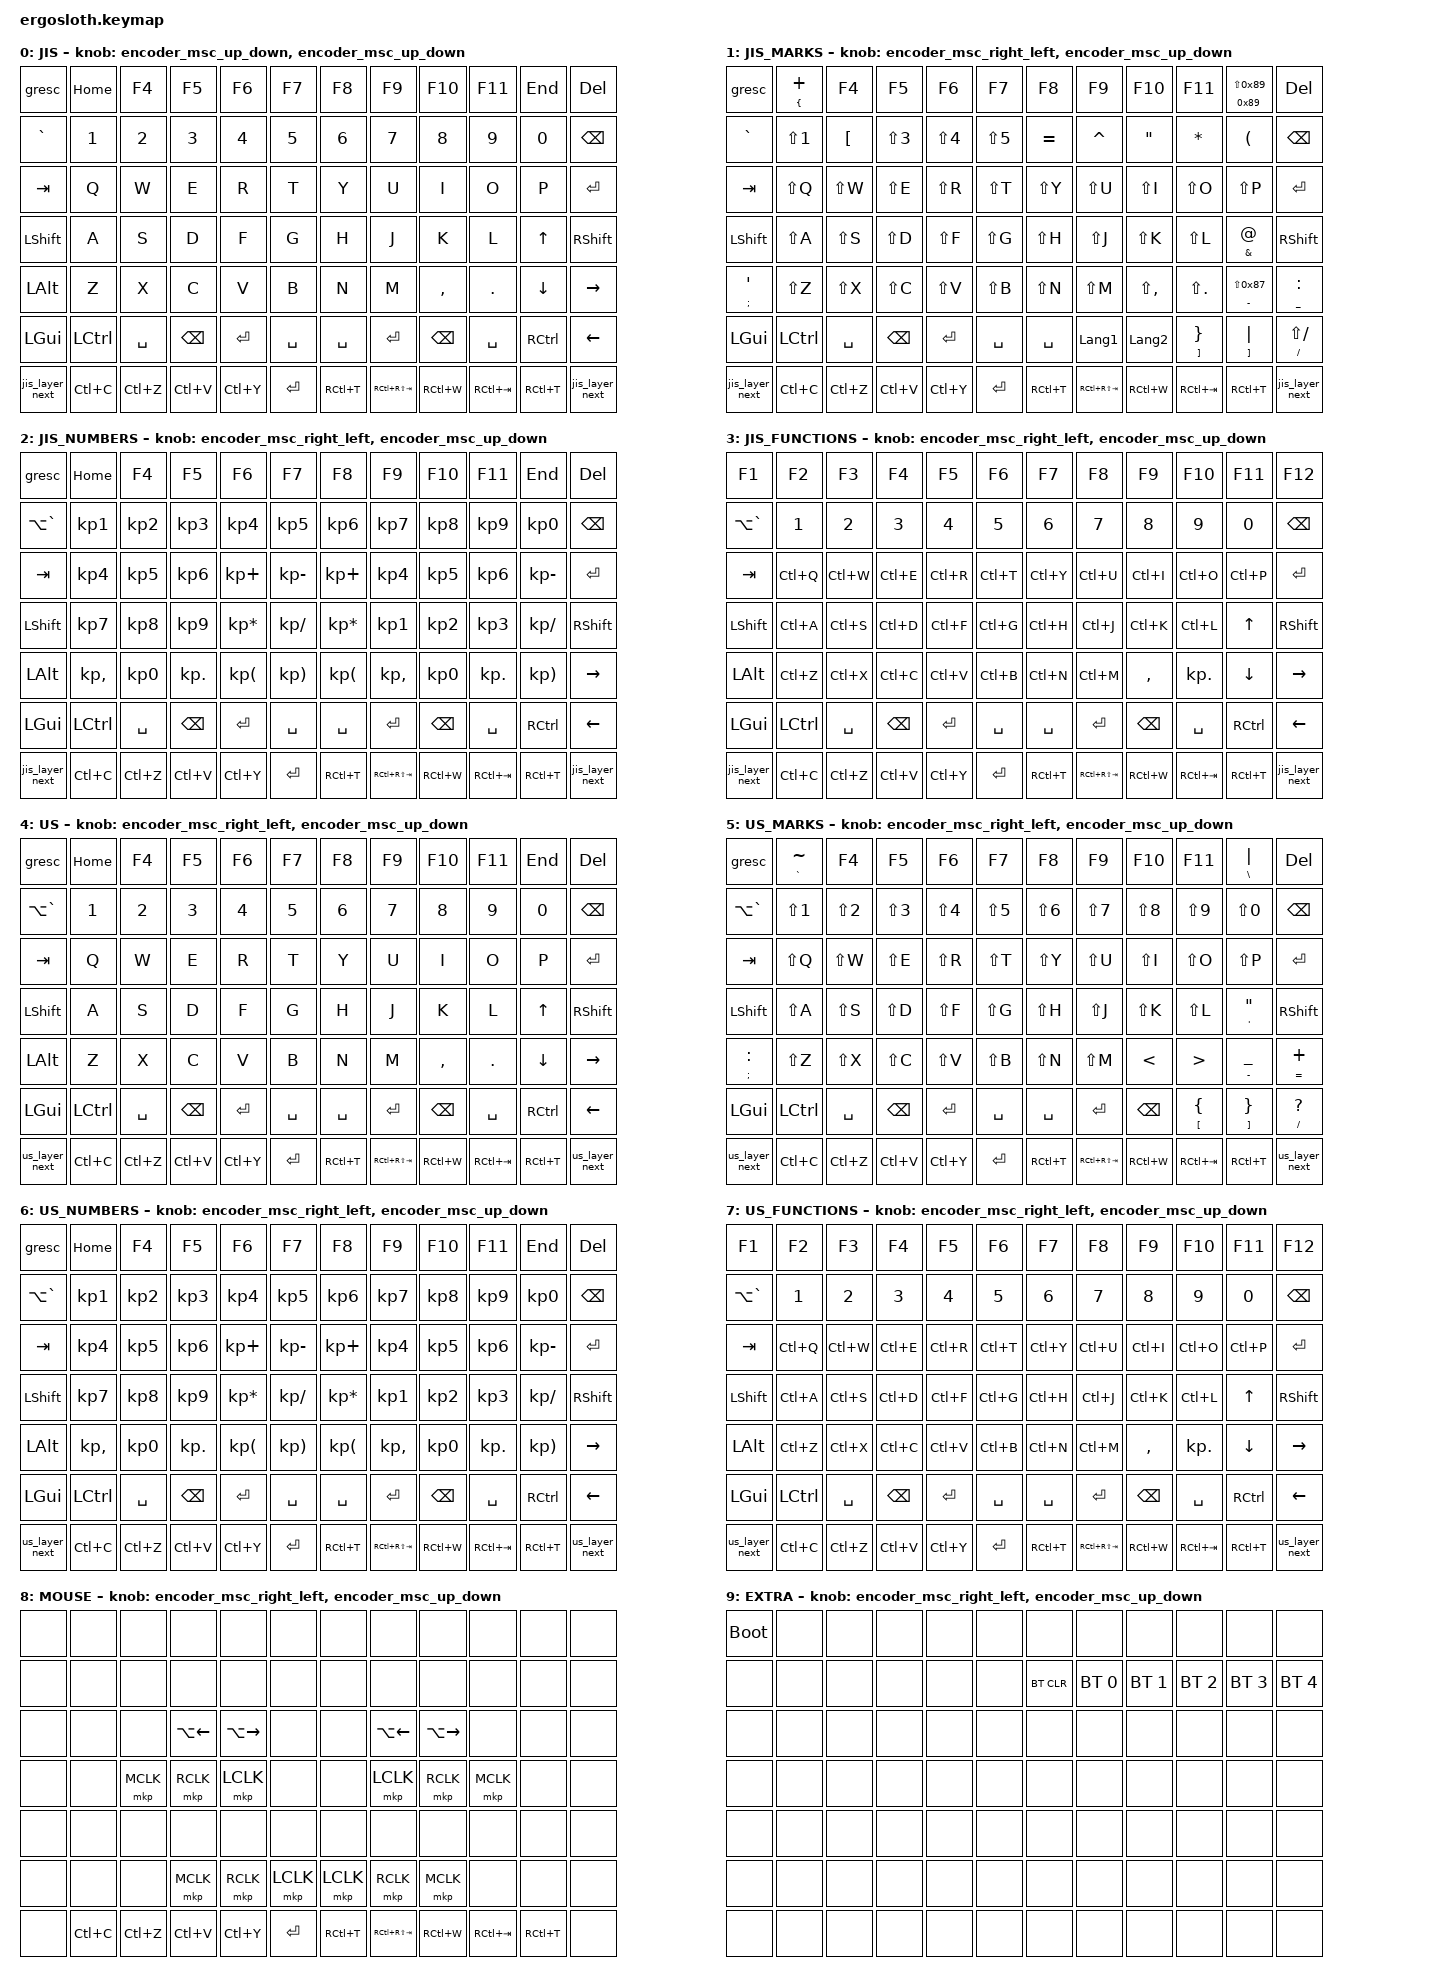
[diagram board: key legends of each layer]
/*
 * Copyright (c) 2020 The ZMK Contributors
 *
 * SPDX-License-Identifier: MIT
 */

#include <input/processors.dtsi>

#define ZMK_POINTING_DEFAULT_SCRL_VAL 50
#define ZMK_MOUSE_SCRL_VAL 50

#include <zephyr/dt-bindings/input/input-event-codes.h>
#include <behaviors.dtsi>
#include <dt-bindings/zmk/bt.h>
#include <dt-bindings/zmk/keys.h>
#include <dt-bindings/zmk/pointing.h>

#define JIS_L       0
#define JIS_MARKS_L 1
#define JIS_NUMS_L  2
#define JIS_FUNCS_L 3
#define US_L        4
#define US_MARKS_L  5
#define US_NUMS_L   6
#define US_FUNCS_L  7
#define MOUSE_L     8
#define EXTRA_L     9

// OS設定を日本語キーボードのまま使用するための変換定義

#define JP_DQUOTE       AT                // "
#define JP_AMPERSAND    CARET             // &
#define JP_QUOTE        AMPERSAND         // '
#define JP_EQUAL        UNDER             // =
#define JP_CARET        EQUAL             // ^
#define JP_YEN          0x89              // ¥
#define JP_PLUS         COLON             // +
#define JP_TILDE        PLUS              // ~
#define JP_PIPE         LS(0x89)          // |
#define JP_AT           LEFT_BRACKET      // @
#define JP_COLON        SINGLE_QUOTE      // :
#define JP_ASTERISK     DOUBLE_QUOTES     // *
#define JP_BACKQUOTE    LEFT_BRACE        // `
#define JP_UNDERSCORE   LS(0x87)          // _
#define JP_LBRACKET     RIGHT_BRACKET     // [
#define JP_RBRACKET     BACKSLASH         // ]
#define JP_LPAREN       ASTERISK          // (
#define JP_RPAREN       LEFT_PARENTHESIS  // )
#define JP_LBRACE       RIGHT_BRACE       // {
#define JP_RBRACE       PIPE              // }
#define JP_KANA         LANGUAGE_1        // かな
#define JP_EISU         LANGUAGE_2        // 英数
#define JP_HANZEN       GRAVE             // 半角/全角

/**************************************************************************/
/*  TrackBall 関連                                                        */

&trackball_right { cpi = <600>; };

&trackball_right_listener { input-processors = <&zip_temp_layer MOUSE_L 5000>; };

// クリック時に10秒間AMLを延長

&mkp_input_listener { input-processors = <&zip_temp_layer MOUSE_L 10000>; };

// キー入力から200ms間はAMLを抑制(AML誤発動防止)

&zip_temp_layer { require-prior-idle-ms = <200>; };

/**************************************************************************/
/*   マウススクロール用設定                                               */

/ {
    input_processors {
        zip_wheel_scaler: zip_wheel_scaler {
            compatible = "zmk,input-processor-scaler";
            #input-processor-cells = <2>;
            type = <INPUT_EV_REL>;
            codes = <INPUT_REL_WHEEL>;
            track-remainders;
        };
    };
};

&msc {
    delay-ms = <0>;
    trigger-period-ms = <10>;
    time-to-max-speed-ms = <0>;
    acceleration-exponent = <0>;
};

&msc_input_listener {
    warp {
        layers = <MOUSE_L>;
        input-processors = <&zip_wheel_scaler 4 1>;
    };

    normal {
        layers = <JIS_L JIS_MARKS_L JIS_NUMS_L JIS_FUNCS_L US_L US_MARKS_L US_NUMS_L US_FUNCS_L EXTRA_L>;
        input-processors = <&zip_wheel_scaler 1 1>;
    };
};

/**************************************************************************/

/ {
    combos {
        compatible = "zmk,combos";

        combo_esc {
            layers = <JIS_L>;
            timeout-ms = <50>;
            key-positions = <0 1>;
            bindings = <&kp ESC>;
        };
    };

    /**************************************************************************/

    macros {
        ctrl_tab: ctrl_tab {
            compatible = "zmk,behavior-macro";
            #binding-cells = <0>;
            wait-ms = <40>;
            tap-ms = <40>;
            bindings =
                <&macro_press>,
                <&kp LCTRL &kp TAB>,
                <&macro_tap_time 1000>,
                <&macro_release>,
                <&kp LCTRL>;
        };

        ctrl_shift_tab: ctrl_shift_tab {
            compatible = "zmk,behavior-macro";
            #binding-cells = <0>;
            wait-ms = <40>;
            tap-ms = <40>;
            bindings =
                <&macro_press>,
                <&kp LCTRL>,
                <&macro_press>,
                <&kp LSHIFT &kp TAB>,
                <&macro_release>,
                <&kp LSHIFT>,
                <&macro_tap_time 1000>,
                <&macro_release>,
                <&kp LCTRL>;
        };

        alt_tab: alt_tab {
            compatible = "zmk,behavior-macro";
            #binding-cells = <0>;
            wait-ms = <40>;
            tap-ms = <40>;
            bindings =
                <&macro_press>,
                <&kp LALT &kp TAB>,
                <&macro_tap_time 1000>,
                <&macro_release>,
                <&kp LALT>;
        };

        alt_shift_tab: alt_shift_tab {
            compatible = "zmk,behavior-macro";
            #binding-cells = <0>;
            wait-ms = <40>;
            tap-ms = <40>;
            bindings =
                <&macro_press>,
                <&kp LALT>,
                <&macro_press>,
                <&kp LSHIFT &kp TAB>,
                <&macro_release>,
                <&kp LSHIFT>,
                <&macro_tap_time 1000>,
                <&macro_release>,
                <&kp LALT>;
        };

        sleep_windows: sleep_windows {
            compatible = "zmk,behavior-macro";
            #binding-cells = <0>;
            wait-ms = <40>;
            tap-ms = <40>;
            bindings =
                <&macro_press>,
                <&kp LGUI &kp X>,
                <&macro_release>,
                <&kp LGUI &kp U>,
                <&macro_tap_time 100>,
                <&kp S>;
        };


        jis_layer_next: jis_layer_next {
            compatible = "zmk,behavior-macro";
            label = "JIS_LAYER_NEXT";
            #binding-cells = <0>;
            // bindings = <&if &layer-0 &to 1 &if &layer-1 &to 2 &if &layer-2 &to 3 &if &layer-3 &to 0>;
            bindings = <&macro_tap_time 1000>, <&macro_tap  &to 0>;
        };

        jis_layer_prev: jis_layer_prev {
            compatible = "zmk,behavior-macro";
            label = "JIS_LAYER_PREV";
            #binding-cells = <0>;
            // bindings = <&if &layer-0 &to 3 &if &layer-1 &to 0 &if &layer-2 &to 1 &if &layer-3 &to 2>;
            bindings = <&macro_tap_time 1000>, <&macro_tap  &to 0>;
        };

        us_layer_next: us_layer_next {
            compatible = "zmk,behavior-macro";
            label = "US_LAYER_NEXT";
            #binding-cells = <0>;
            // bindings = <&if &layer-4 &to 5 &if &layer-5 &to 6 &if &layer-6 &to 7 &if &layer-7 &to 4>;
            bindings = <&macro_tap_time 1000>, <&macro_tap  &to 0>;
        };

        us_layer_prev: us_layer_prev {
            compatible = "zmk,behavior-macro";
            label = "US_LAYER_PREV";
            #binding-cells = <0>;
            // bindings = <&if &layer-4 &to 7 &if &layer-5 &to 4 &if &layer-6 &to 5 &if &layer-7 &to 6>;
            bindings = <&macro_tap_time 1000>, <&macro_tap  &to 0>;
        };

    };

    /**************************************************************************/

    behaviors {
        td_bspc: tap_dance_0 {
            compatible = "zmk,behavior-tap-dance";
            #binding-cells = <0>;
            tapping-term-ms = <200>;
            bindings = <&lt JIS_FUNCS_L BSPC>, <&kp BSPC>;
        };

        td_spc: tap_dance_1 {
            compatible = "zmk,behavior-tap-dance";
            #binding-cells = <0>;
            tapping-term-ms = <200>;
            bindings = <&lt JIS_FUNCS_L SPACE>, <&kp SPACE>;
        };

        mouse_scroll: mouse_wheel_scroll {
            compatible = "zmk,behavior-sensor-rotate-var";
            #sensor-binding-cells = <2>;
            bindings = <&msc>, <&msc>;

            tap-ms = <25>;
        };

        mod_mkp: mod_mkp {
            compatible = "zmk,behavior-hold-tap";
            label = "MOD_MKP";
            bindings = <&kp>, <&mkp>;

            #binding-cells = <2>;
            tapping-term-ms = <150>;
        };

        tog_off: toggle_layer_off {
            compatible = "zmk,behavior-toggle-layer";
            #binding-cells = <1>;
            display-name = "Toggle Layer Off";
            toggle-mode = "off";
        };

        ime_alt: ime_alt {
            compatible = "zmk,behavior-hold-tap";
            label = "IME_ALT";
            bindings = <&kp>, <&kp>;

            #binding-cells = <2>;
            tapping-term-ms = <200>;
            flavor = "tap-preferred";
        };

        encoder_msc_up_down: encoder_msc_up_down {
            compatible = "zmk,behavior-sensor-rotate";
            label = "ENCODER_MSC_UP_DOWN";
            #sensor-binding-cells = <0>;
            bindings = <&msc SCRL_UP>, <&msc SCRL_DOWN>;

            tap-ms = <20>;
        };

        encoder_msc_right_left: encoder_msc_right_left {
            compatible = "zmk,behavior-sensor-rotate";
            label = "ENCODER_MSC_RIGHT_LEFT";
            #sensor-binding-cells = <0>;
            bindings = <&msc SCRL_RIGHT>, <&msc SCRL_LEFT>;

            tap-ms = <20>;
        };

        encoder_vol_up_down: encoder_vol_up_down {
            compatible = "zmk,behavior-sensor-rotate";
            #sensor-binding-cells = <0>;
            bindings = <&kp C_VOLUME_UP>, <&kp C_VOLUME_DOWN>;

            tap-ms = <20>;
        };

        encoder_bri_up_down: encoder_bri_up_down {
            compatible = "zmk,behavior-sensor-rotate";
            #sensor-binding-cells = <0>;
            bindings = <&kp C_BRIGHTNESS_INC>, <&kp C_BRIGHTNESS_DEC>;

            tap-ms = <20>;
        };

        encoder_ctrl_tab: encoder_ctrl_tab {
            compatible = "zmk,behavior-sensor-rotate";
            #sensor-binding-cells = <0>;
            bindings = <&ctrl_tab>, <&ctrl_shift_tab>;

            tap-ms = <20>;
        };

        encoder_alt_tab: encoder_alt_tab {
            compatible = "zmk,behavior-sensor-rotate";
            #sensor-binding-cells = <0>;
            bindings = <&alt_tab>, <&alt_shift_tab>;

            tap-ms = <20>;
        };

        encoder_next_prev: encoder_next_prev {
            compatible = "zmk,behavior-sensor-rotate";
            #sensor-binding-cells = <0>;
            bindings = <&kp LA(RIGHT)>, <&kp LA(LEFT)>;

            tap-ms = <20>;
        };

        encoder_tab: encoder_tab {
            compatible = "zmk,behavior-sensor-rotate";
            #sensor-binding-cells = <0>;
            bindings = <&kp TAB>, <&kp LS(TAB)>;

            tap-ms = <20>;
        };


        encoder_jis_layer: encoder_jis_layer {
            compatible = "zmk,behavior-sensor-rotate";
            #sensor-binding-cells = <0>;
            bindings = <&jis_layer_next>, <&jis_layer_prev>;
            tap-ms = <20>;
        };

        encoder_us_layer: encoder_us_layer {
            compatible = "zmk,behavior-sensor-rotate";
            #sensor-binding-cells = <0>;
            bindings = <&us_layer_next>, <&us_layer_prev>;
            tap-ms = <20>;
        };

    };

    /**************************************************************************/

    keymap {
        compatible = "zmk,keymap";

        //               | SW2  | SW3  | SW4  | SW5  |   | SW6  | SW7  | SW8  | SW9  |
        // | SW0  | SW1  | SW14 | SW15 | SW16 | SW17 |   | SW18 | SW19 | SW20 | SW21 | SW10 | SW11 |
        // | SW12 | SW13 | SW26 | SW27 | SW28 | SW29 |   | SW30 | SW31 | SW32 | SW33 | SW22 | SW23 |
        // | SW24 | SW25 | SW38 | SW39 | SW40 | SW41 |   | SW42 | SW43 | SW44 | SW45 | SW34 | SW35 |
        // | SW36 | SW37 | SW50 | SW51 | SW52 | SW53 |   | SW54 | SW55 | SW56 | SW57 | SW46 | SW47 |
        // | SW48 | SW49 | SW60 | SW61 | SW62 | (LAJS)   (RAJS) | SW69 | SW70 | SW71 | SW58 | SW59 |
        //                                  (TouchPad)
        // 		                              | SW65 |   | SW66 |	    (TrackBall)
        // 							   | SW64 |					| SW67 |
        // | SW72 |				| SW63 |							   | SW68 |				| SW83 |
        //    (LeftRotaryEncoder)                                             (RightRotaryEncoder)
        //		  | SW73 |															 | SW78 |
        // | SW74 | SW77 | SW76 |											  | SW79 | SW82 | SW81 |
        // 		  | SW75 |															 | SW80 |
        //                                                         ||
        //                                                       __||__
        //                                                        \  /
        //                                                         \/
        // | SW0  | SW1  | SW2  | SW3  | SW4  | SW5  |   | SW6  | SW7  | SW8  | SW9  | SW10 | SW11 |
        // | SW12 | SW13 | SW14 | SW15 | SW16 | SW17 |   | SW18 | SW19 | SW20 | SW21 | SW22 | SW23 |
        // | SW24 | SW25 | SW26 | SW27 | SW28 | SW29 |   | SW30 | SW31 | SW32 | SW33 | SW34 | SW35 |
        // | SW36 | SW37 | SW38 | SW39 | SW40 | SW41 |   | SW42 | SW43 | SW44 | SW45 | SW46 | SW47 |
        // | SW48 | SW49 | SW50 | SW51 | SW52 | SW53 |   | SW54 | SW55 | SW56 | SW57 | SW58 | SW59 |
        // | SW60 | SW61 | SW62 | SW63 | SW64 | SW65 |   | SW66 | SW67 | SW68 | SW69 | SW70 | SW71 |
        // | SW72 | SW73 | SW74 | SW75 | SW76 | SW77 |   | SW78 | SW79 | SW80 | SW81 | SW82 | SW83 |

        jis_layer {
            display-name = "JIS";

            // -----------------------------------------------------------------------------------------
            //               |  F4  |  F5  |  F6  |  F7  |   |  F8  |  F9  | F10  | F11  |
            // |  ESC | HOME |   2  |   3  |   4  |   5  |   |   6  |   7  |   8  |   9  |  END |  DEL |
            // |  E/J |   1  |   W  |   E  |   R  |   T  |   |   Y  |   U  |   I  |   O  |   0  | BKSP |
            // |  TAB |   Q  |   S  |   D  |   F  |   G  |   |   H  |   J  |   K  |   L  |   P  | ENTR |
            // | LSft |   A  |   X  |   C  |   V  |   B  |   |   N  |   M  |   ,  |   .  |   ↑  | RSft |
            // | LAlt |   Z  |  GUI | LCtr | SPCE |                 | SPCE | RCtr |   ←  |   ↓  |   →  |
            // 		                      	
            //                                    | SPCE |   | SPCE |
            // 							   | ENTR |					| ENTR |
            // | layr |				| BKSP |							   | BKSP |				| layr |
            //
            //		  | CtrC |															 | CtrT |
            // | CtrZ | Entr | CtrY |											  | CSTb | Entr | CtTb |
            // 		  | CtrV |															 | CtrW |
            // -----------------------------------------------------------------------------------------
            // |  ESC | HOME |  F4  |  F5  |  F6  |  F7  |   |  F8  |  F9  | F10  | F11  |  END |  DEL |
            // |  E/J |   1  |   2  |   3  |   4  |   5  |   |   6  |   7  |   8  |   9  |   0  | BKSP |
            // |  TAB |   Q  |   W  |   E  |   R  |   T  |   |   Y  |   U  |   I  |   O  |   P  | ENTR |
            // | LSft |   A  |   S  |   D  |   F  |   G  |   |   H  |   J  |   K  |   L  |   ↑  | RSft |
            // | LAlt |   Z  |   X  |   C  |   V  |   B  |   |   N  |   M  |   ,  |   .  |   ↓  |   →  |
            // |  GUI | LCtr | SPCE | BKSP | ENTR | SPCE |   | SPCE | ENTR | BKSP | SPCE | RCtr |   ←  |
            // | lyr1 | CtrC | CtrZ | CtrV | CtrY | Entr |   | CtrT | BTab | CtrW | NTab | CtrT | lyr1 |

            bindings = <
&gresc     &kp HOME   &kp F4     &kp F5         &kp F6     &kp F7     &kp F8     &kp F9           &kp F10        &kp F11      &kp END    &kp DEL
&kp GRAVE  &kp N1     &kp N2     &kp N3         &kp N4     &kp N5     &kp N6     &kp N7           &kp N8         &kp N9       &kp N0     &kp BACKSPACE
&kp TAB    &kp Q      &kp W      &kp E          &kp R      &kp T      &kp Y      &kp U            &kp I          &kp O        &kp P      &kp ENTER
&kp LSHFT  &kp A      &kp S      &kp D          &kp F      &kp G      &kp H      &kp J            &kp K          &kp L        &kp UP     &kp RSHFT
&kp LALT   &kp Z      &kp X      &kp C          &kp V      &kp B      &kp N      &kp M            &kp COMMA      &kp PERIOD   &kp DOWN   &kp RIGHT
&kp LGUI   &kp LCTRL  &kp SPACE  &kp BACKSPACE  &kp ENTER  &kp SPACE  &kp SPACE  &kp ENTER        &kp BACKSPACE  &kp SPACE    &kp RCTRL  &kp LEFT
&jis_layer_next  &kp LC(C)  &kp LC(Z)  &kp LC(V)      &kp LC(Y)  &kp ENTER  &kp RC(T)  &kp RC(RS(TAB))  &kp RC(W)      &kp RC(TAB)  &kp RC(T)  &jis_layer_next
            >;

            sensor-bindings = <&encoder_msc_up_down>, <&encoder_msc_up_down>;
        };

        jis_mark_layer {
            display-name = "JIS_MARKS";

            // -----------------------------------------------------------------------------------------
            // |  ESC |  ` ~ |  F4  |  F5  |  F6  |  F7  |   |  F8  |  F9  | F10  | F11  |  \ | |  DEL |
            // |  E/J |   !  |   @  |   #  |   $  |   %  |   |   ^  |   &  |   *  |   (  |   )  | BKSP |
            // |  TAB |   Q  |   W  |   E  |   R  |   T  |   |   Y  |   U  |   I  |   O  |   P  | ENTR |
            // | LSft |   A  |   S  |   D  |   F  |   G  |   |   H  |   J  |   K  |   L  |  ' " | RSft |
            // |  ; : |   Z  |   X  |   C  |   V  |   B  |   |   N  |   M  |   <  |   >  |  - _ |  = + |
            // |  GUI | LCtr | SPCE | BKSP | ENTR | SPCE |   | SPCE | Kana | EiSu |  [ { |  ] } |  / ? |
            // | lyr2 | CtrC | CtrZ | CtrV | CtrY | Entr |   | CtrT | BTab | CtrW | NTab | CtrT | lyr2 |

            bindings = <
&gresc                      &mt LEFT_BRACE PLUS  &kp F4            &kp F5         &kp F6      &kp F7      &kp F8     &kp F9           &kp F10            &kp F11                        &mt 0x89 LS(0x89)       &kp DEL
&kp GRAVE                   &kp LS(N1)           &kp LEFT_BRACKET  &kp LS(N3)     &kp LS(N4)  &kp LS(N5)  &kp EQUAL  &kp CARET        &kp DOUBLE_QUOTES  &kp ASTERISK                   &kp LEFT_PARENTHESIS    &kp BACKSPACE
&kp TAB                     &kp LS(Q)            &kp LS(W)         &kp LS(E)      &kp LS(R)   &kp LS(T)   &kp LS(Y)  &kp LS(U)        &kp LS(I)          &kp LS(O)                      &kp LS(P)               &kp ENTER
&kp LSHFT                   &kp LS(A)            &kp LS(S)         &kp LS(D)      &kp LS(F)   &kp LS(G)   &kp LS(H)  &kp LS(J)        &kp LS(K)          &kp LS(L)                      &mt AMPERSAND AT        &kp RSHFT
&mt SEMICOLON SINGLE_QUOTE  &kp LS(Z)            &kp LS(X)         &kp LS(C)      &kp LS(V)   &kp LS(B)   &kp LS(N)  &kp LS(M)        &kp LS(COMMA)      &kp LS(PERIOD)                 &mt MINUS LS(0x87)      &mt UNDER COLON
&kp LGUI                    &kp LCTRL            &kp SPACE         &kp BACKSPACE  &kp ENTER   &kp SPACE   &kp SPACE  &kp LANGUAGE_1   &kp LANGUAGE_2     &mt RIGHT_BRACKET RIGHT_BRACE  &mt RIGHT_BRACKET PIPE  &mt SLASH LS(SLASH)
&jis_layer_next             &kp LC(C)            &kp LC(Z)         &kp LC(V)      &kp LC(Y)   &kp ENTER   &kp RC(T)  &kp RC(RS(TAB))  &kp RC(W)          &kp RC(TAB)                    &kp RC(T)               &jis_layer_next
            >;

            sensor-bindings = <&encoder_msc_right_left &encoder_msc_up_down>;
        };

        jis_num_layer {
            display-name = "JIS_NUMBERS";

            // -----------------------------------------------------------------------------------------
            // |  ESC | HOME |  F4  |  F5  |  F6  |  F7  |   |  F8  |  F9  | F10  | F11  |  END |  DEL |
            // |  E/J |   1  |   2  |   3  |   4  |   5  |   |   6  |   7  |   8  |   9  |   0  | BKSP |
            // |  TAB |   4  |   5  |   6  |   +  |   -  |   |   +  |   4  |   5  |   6  |   -  | ENTR |
            // | LSft |   7  |   8  |   9  |   *  |   /  |   |   *  |   1  |   2  |   3  |   /  | RSft |
            // | LAlt |   ,  |   0  |   .  |   (  |   )  |   |   (  |   ,  |   0  |   .  |   )  |   →  |
            // |  GUI | LCtr | SPCE | BKSP | ENTR | SPCE |   | SPCE | ENTR | BKSP | SPCE | RCtr |   ←  |
            // | lyr5 | CtrC | CtrZ | CtrV | CtrY | Entr |   | CtrT | BTab | CtrW | NTab | CtrT | lyr5 |

            bindings = <
&gresc         &kp HOME      &kp F4     &kp F5         &kp F6           &kp F7         &kp F8           &kp F9           &kp F10        &kp F11      &kp END        &kp DEL
&kp LA(GRAVE)  &kp KP_N1     &kp KP_N2  &kp KP_N3      &kp KP_N4        &kp KP_N5      &kp KP_N6        &kp KP_N7        &kp KP_N8      &kp KP_N9    &kp KP_N0      &kp BACKSPACE
&kp TAB        &kp KP_N4     &kp KP_N5  &kp KP_N6      &kp KP_PLUS      &kp KP_MINUS   &kp KP_PLUS      &kp KP_N4        &kp KP_N5      &kp KP_N6    &kp KP_MINUS   &kp ENTER
&kp LSHFT      &kp KP_N7     &kp KP_N8  &kp KP_N9      &kp KP_MULTIPLY  &kp KP_DIVIDE  &kp KP_MULTIPLY  &kp KP_N1        &kp KP_N2      &kp KP_N3    &kp KP_DIVIDE  &kp RSHFT
&kp LALT       &kp KP_COMMA  &kp KP_N0  &kp KP_DOT     &kp KP_LPAR      &kp KP_RPAR    &kp KP_LPAR      &kp KP_COMMA     &kp KP_N0      &kp KP_DOT   &kp KP_RPAR    &kp RIGHT
&kp LGUI       &kp LCTRL     &kp SPACE  &kp BACKSPACE  &kp ENTER        &kp SPACE      &kp SPACE        &kp ENTER        &kp BACKSPACE  &kp SPACE    &kp RCTRL      &kp LEFT
&jis_layer_next   &kp LC(C)     &kp LC(Z)  &kp LC(V)      &kp LC(Y)        &kp ENTER      &kp RC(T)        &kp RC(RS(TAB))  &kp RC(W)      &kp RC(TAB)  &kp RC(T)      &jis_layer_next
            >;

            sensor-bindings = <&encoder_msc_right_left &encoder_msc_up_down>;
        };

        jis_func_layer {
            display-name = "JIS_FUNCTIONS";

            // -----------------------------------------------------------------------------------------
            // |  F1  |  F2  |  F3  |  F4  |  F5  |  F6  |   |  F7  |  F8  |  F9  | F10  |  F11 |  F12 |
            // |  E/J |   1  |   2  |   3  |   4  |   5  |   |   6  |   7  |   8  |   9  |   0  | BKSP |
            // |  TAB | CtrQ | CtrW | CtrE | CtrR | CtrT |   | CtrY | CtrU | CtrI | CtrO | CtrP | ENTR |
            // | LSft | CtrA | CtrS | CtrD | CtrF | CtrG |   | CtrH | CtrJ | CtrK | CtrL |   ↑  | RSft |
            // | LAlt | CtrZ | CtrX | CtrC | CtrV | CtrB |   | CtrN | CtrM |   ,  |   .  |   ↓  |   →  |
            // |  GUI | LCtr | SPCE | BKSP | ENTR | SPCE |   | SPCE | ENTR | BKSP | SPCE | RCtr |   ←  |
            // | lyr0 | CtrC | CtrZ | CtrV | CtrY | Entr |   | CtrT | BTab | CtrW | NTab | CtrT | lyr0 |

            bindings = <
&kp F1         &kp F2     &kp F3     &kp F4         &kp F5     &kp F6     &kp F7     &kp F8           &kp F9         &kp F10      &kp F11    &kp F12
&kp LA(GRAVE)  &kp N1     &kp N2     &kp N3         &kp N4     &kp N5     &kp N6     &kp N7           &kp N8         &kp N9       &kp N0     &kp BACKSPACE
&kp TAB        &kp LC(Q)  &kp LC(W)  &kp LC(E)      &kp LC(R)  &kp LC(T)  &kp LC(Y)  &kp LC(U)        &kp LC(I)      &kp LC(O)    &kp LC(P)  &kp ENTER
&kp LSHFT      &kp LC(A)  &kp LC(S)  &kp LC(D)      &kp LC(F)  &kp LC(G)  &kp LC(H)  &kp LC(J)        &kp LC(K)      &kp LC(L)    &kp UP     &kp RSHFT
&kp LALT       &kp LC(Z)  &kp LC(X)  &kp LC(C)      &kp LC(V)  &kp LC(B)  &kp LC(N)  &kp LC(M)        &kp COMMA      &kp KP_DOT   &kp DOWN   &kp RIGHT
&kp LGUI       &kp LCTRL  &kp SPACE  &kp BACKSPACE  &kp ENTER  &kp SPACE  &kp SPACE  &kp ENTER        &kp BACKSPACE  &kp SPACE    &kp RCTRL  &kp LEFT
&jis_layer_next  &kp LC(C)  &kp LC(Z)  &kp LC(V)      &kp LC(Y)  &kp ENTER  &kp RC(T)  &kp RC(RS(TAB))  &kp RC(W)      &kp RC(TAB)  &kp RC(T)  &jis_layer_next
            >;

            sensor-bindings = <&encoder_msc_right_left &encoder_msc_up_down>;
        };

        us_layer {
            display-name = "US";

            // -----------------------------------------------------------------------------------------
            // |  ESC | HOME |  F4  |  F5  |  F6  |  F7  |   |  F8  |  F9  | F10  | F11  |  END |  DEL |
            // |  E/J |   1  |   2  |   3  |   4  |   5  |   |   6  |   7  |   8  |   9  |   0  | BKSP |
            // |  TAB |   Q  |   W  |   E  |   R  |   T  |   |   Y  |   U  |   I  |   O  |   P  | ENTR |
            // | LSft |   A  |   S  |   D  |   F  |   G  |   |   H  |   J  |   K  |   L  |   ↑  | RSft |
            // | LAlt |   Z  |   X  |   C  |   V  |   B  |   |   N  |   M  |   ,  |   .  |   ↓  |   →  |
            // |  GUI | LCtr | SPCE | BKSP | ENTR | SPCE |   | SPCE | ENTR | BKSP | SPCE | RCtr |   ←  |
            // | lyr3 | CtrC | CtrZ | CtrV | CtrY | Entr |   | CtrT | BTab | CtrW | NTab | CtrT | lyr3 |

            bindings = <
&gresc         &kp HOME   &kp F4     &kp F5         &kp F6     &kp F7     &kp F8     &kp F9           &kp F10        &kp F11      &kp END    &kp DEL
&kp LA(GRAVE)  &kp N1     &kp N2     &kp N3         &kp N4     &kp N5     &kp N6     &kp N7           &kp N8         &kp N9       &kp N0     &kp BACKSPACE
&kp TAB        &kp Q      &kp W      &kp E          &kp R      &kp T      &kp Y      &kp U            &kp I          &kp O        &kp P      &kp ENTER
&kp LSHFT      &kp A      &kp S      &kp D          &kp F      &kp G      &kp H      &kp J            &kp K          &kp L        &kp UP     &kp RSHFT
&kp LALT       &kp Z      &kp X      &kp C          &kp V      &kp B      &kp N      &kp M            &kp COMMA      &kp PERIOD   &kp DOWN   &kp RIGHT
&kp LGUI       &kp LCTRL  &kp SPACE  &kp BACKSPACE  &kp ENTER  &kp SPACE  &kp SPACE  &kp ENTER        &kp BACKSPACE  &kp SPACE    &kp RCTRL  &kp LEFT
&us_layer_next   &kp LC(C)  &kp LC(Z)  &kp LC(V)      &kp LC(Y)  &kp ENTER  &kp RC(T)  &kp RC(RS(TAB))  &kp RC(W)      &kp RC(TAB)  &kp RC(T)  &us_layer_next
            >;

            sensor-bindings = <&encoder_msc_right_left &encoder_msc_up_down>;
        };

        us_mark_layer {
            display-name = "US_MARKS";

            // -----------------------------------------------------------------------------------------
            // |  ESC |  ` ~ |  F4  |  F5  |  F6  |  F7  |   |  F8  |  F9  | F10  | F11  |  \ | |  DEL |
            // |  E/J |   !  |   @  |   #  |   $  |   %  |   |   ^  |   &  |   *  |   (  |   )  | BKSP |
            // |  TAB |   Q  |   W  |   E  |   R  |   T  |   |   Y  |   U  |   I  |   O  |   P  | ENTR |
            // | LSft |   A  |   S  |   D  |   F  |   G  |   |   H  |   J  |   K  |   L  |  ' " | RSft |
            // |  ; : |   Z  |   X  |   C  |   V  |   B  |   |   N  |   M  |   <  |   >  |  - _ |  = + |
            // |  GUI | LCtr | SPCE | BKSP | ENTR | SPCE |   | SPCE | ENTR | BKSP |  [ { |  ] } |  / ? |
            // | lyr4 | CtrC | CtrZ | CtrV | CtrY | Entr |   | CtrT | BTab | CtrW | NTab | CtrT | lyr4 |

            bindings = <
&gresc               &mt GRAVE TILDE  &kp F4      &kp F5         &kp F6      &kp F7      &kp F8      &kp F9           &kp F10        &kp F11        &mt BSLH PIPE    &kp DEL
&kp LA(GRAVE)        &kp LS(N1)       &kp LS(N2)  &kp LS(N3)     &kp LS(N4)  &kp LS(N5)  &kp LS(N6)  &kp LS(N7)       &kp LS(N8)     &kp LS(N9)     &kp LS(N0)       &kp BACKSPACE
&kp TAB              &kp LS(Q)        &kp LS(W)   &kp LS(E)      &kp LS(R)   &kp LS(T)   &kp LS(Y)   &kp LS(U)        &kp LS(I)      &kp LS(O)      &kp LS(P)        &kp ENTER
&kp LSHFT            &kp LS(A)        &kp LS(S)   &kp LS(D)      &kp LS(F)   &kp LS(G)   &kp LS(H)   &kp LS(J)        &kp LS(K)      &kp LS(L)      &mt APOS DQT     &kp RSHFT
&mt SEMICOLON COLON  &kp LS(Z)        &kp LS(X)   &kp LS(C)      &kp LS(V)   &kp LS(B)   &kp LS(N)   &kp LS(M)        &kp LT         &kp GT         &mt MINUS UNDER  &mt EQUAL PLUS
&kp LGUI             &kp LCTRL        &kp SPACE   &kp BACKSPACE  &kp ENTER   &kp SPACE   &kp SPACE   &kp ENTER        &kp BACKSPACE  &mt LBKT LBRC  &mt RBKT RBRC    &mt SLASH QMARK
&us_layer_next       &kp LC(C)        &kp LC(Z)   &kp LC(V)      &kp LC(Y)   &kp ENTER   &kp RC(T)   &kp RC(RS(TAB))  &kp RC(W)      &kp RC(TAB)    &kp RC(T)        &us_layer_next
            >;

            sensor-bindings = <&encoder_msc_right_left &encoder_msc_up_down>;
        };

        us_num_layer {
            display-name = "US_NUMBERS";

            // -----------------------------------------------------------------------------------------
            // |  ESC | HOME |  F4  |  F5  |  F6  |  F7  |   |  F8  |  F9  | F10  | F11  |  END |  DEL |
            // |  E/J |   1  |   2  |   3  |   4  |   5  |   |   6  |   7  |   8  |   9  |   0  | BKSP |
            // |  TAB |   4  |   5  |   6  |   +  |   -  |   |   +  |   4  |   5  |   6  |   -  | ENTR |
            // | LSft |   7  |   8  |   9  |   *  |   /  |   |   *  |   1  |   2  |   3  |   /  | RSft |
            // | LAlt |   ,  |   0  |   .  |   (  |   )  |   |   (  |   ,  |   0  |   .  |   )  |   →  |
            // |  GUI | LCtr | SPCE | BKSP | ENTR | SPCE |   | SPCE | ENTR | BKSP | SPCE | RCtr |   ←  |
            // | lyr5 | CtrC | CtrZ | CtrV | CtrY | Entr |   | CtrT | BTab | CtrW | NTab | CtrT | lyr5 |

            bindings = <
&gresc         &kp HOME      &kp F4     &kp F5         &kp F6           &kp F7         &kp F8           &kp F9           &kp F10        &kp F11      &kp END        &kp DEL
&kp LA(GRAVE)  &kp KP_N1     &kp KP_N2  &kp KP_N3      &kp KP_N4        &kp KP_N5      &kp KP_N6        &kp KP_N7        &kp KP_N8      &kp KP_N9    &kp KP_N0      &kp BACKSPACE
&kp TAB        &kp KP_N4     &kp KP_N5  &kp KP_N6      &kp KP_PLUS      &kp KP_MINUS   &kp KP_PLUS      &kp KP_N4        &kp KP_N5      &kp KP_N6    &kp KP_MINUS   &kp ENTER
&kp LSHFT      &kp KP_N7     &kp KP_N8  &kp KP_N9      &kp KP_MULTIPLY  &kp KP_DIVIDE  &kp KP_MULTIPLY  &kp KP_N1        &kp KP_N2      &kp KP_N3    &kp KP_DIVIDE  &kp RSHFT
&kp LALT       &kp KP_COMMA  &kp KP_N0  &kp KP_DOT     &kp KP_LPAR      &kp KP_RPAR    &kp KP_LPAR      &kp KP_COMMA     &kp KP_N0      &kp KP_DOT   &kp KP_RPAR    &kp RIGHT
&kp LGUI       &kp LCTRL     &kp SPACE  &kp BACKSPACE  &kp ENTER        &kp SPACE      &kp SPACE        &kp ENTER        &kp BACKSPACE  &kp SPACE    &kp RCTRL      &kp LEFT
&us_layer_next  &kp LC(C)     &kp LC(Z)  &kp LC(V)      &kp LC(Y)        &kp ENTER      &kp RC(T)        &kp RC(RS(TAB))  &kp RC(W)      &kp RC(TAB)  &kp RC(T)      &us_layer_next
            >;

            sensor-bindings = <&encoder_msc_right_left &encoder_msc_up_down>;
        };

        us_func_layer {
            display-name = "US_FUNCTIONS";

            // -----------------------------------------------------------------------------------------
            // |  F1  |  F2  |  F3  |  F4  |  F5  |  F6  |   |  F7  |  F8  |  F9  | F10  |  F11 |  F12 |
            // |  E/J |   1  |   2  |   3  |   4  |   5  |   |   6  |   7  |   8  |   9  |   0  | BKSP |
            // |  TAB | CtrQ | CtrW | CtrE | CtrR | CtrT |   | CtrY | CtrU | CtrI | CtrO | CtrP | ENTR |
            // | LSft | CtrA | CtrS | CtrD | CtrF | CtrG |   | CtrH | CtrJ | CtrK | CtrL |   ↑  | RSft |
            // | LAlt | CtrZ | CtrX | CtrC | CtrV | CtrB |   | CtrN | CtrM |   ,  |   .  |   ↓  |   →  |
            // |  GUI | LCtr | SPCE | BKSP | ENTR | SPCE |   | SPCE | ENTR | BKSP | SPCE | RCtr |   ←  |
            // | lyr0 | CtrC | CtrZ | CtrV | CtrY | Entr |   | CtrT | BTab | CtrW | NTab | CtrT | lyr0 |

            bindings = <
&kp F1         &kp F2     &kp F3     &kp F4         &kp F5     &kp F6     &kp F7     &kp F8           &kp F9         &kp F10      &kp F11    &kp F12
&kp LA(GRAVE)  &kp N1     &kp N2     &kp N3         &kp N4     &kp N5     &kp N6     &kp N7           &kp N8         &kp N9       &kp N0     &kp BACKSPACE
&kp TAB        &kp LC(Q)  &kp LC(W)  &kp LC(E)      &kp LC(R)  &kp LC(T)  &kp LC(Y)  &kp LC(U)        &kp LC(I)      &kp LC(O)    &kp LC(P)  &kp ENTER
&kp LSHFT      &kp LC(A)  &kp LC(S)  &kp LC(D)      &kp LC(F)  &kp LC(G)  &kp LC(H)  &kp LC(J)        &kp LC(K)      &kp LC(L)    &kp UP     &kp RSHFT
&kp LALT       &kp LC(Z)  &kp LC(X)  &kp LC(C)      &kp LC(V)  &kp LC(B)  &kp LC(N)  &kp LC(M)        &kp COMMA      &kp KP_DOT   &kp DOWN   &kp RIGHT
&kp LGUI       &kp LCTRL  &kp SPACE  &kp BACKSPACE  &kp ENTER  &kp SPACE  &kp SPACE  &kp ENTER        &kp BACKSPACE  &kp SPACE    &kp RCTRL  &kp LEFT
&us_layer_next  &kp LC(C)  &kp LC(Z)  &kp LC(V)      &kp LC(Y)  &kp ENTER  &kp RC(T)  &kp RC(RS(TAB))  &kp RC(W)      &kp RC(TAB)  &kp RC(T)  &us_layer_next
            >;

            sensor-bindings = <&encoder_msc_right_left &encoder_msc_up_down>;
        };

        mouse_layer {
            display-name = "MOUSE";

            // -----------------------------------------------------------------------------------------
            // |      |      |      |      |      |      |   |      |      |      |      |      |      |
            // |      |      |      |      |      |      |   |      |      |      |      |      |      |
            // |      |      |      | Prev | Next |      |   |      | Prev | Next |      |      |      |
            // |      |      | MCLK | RCLK | LCLK |      |   |      | LCLK | RCLK | MCLK |      |      |
            // |      |      |      |      |      |      |   |      |      |      |      |      |      |
            // |      |      |      | MCLK | RCLK | LCLK |   | LCLK | RCLK | MCLK |      |      |      |
            // |      | CtrC | CtrZ | CtrV | CtrY | Entr |   | CtrT | BTab | CtrW | NTab | CtrT |      |

            bindings = <
&none  &none      &none      &none         &none          &none      &none      &none            &none          &none        &none      &none
&none  &none      &none      &none         &none          &none      &none      &none            &none          &none        &none      &none
&none  &none      &none      &kp LA(LEFT)  &kp LA(RIGHT)  &none      &none      &kp LA(LEFT)     &kp LA(RIGHT)  &none        &none      &none
&none  &none      &mkp MCLK  &mkp RCLK     &mkp LCLK      &none      &none      &mkp LCLK        &mkp RCLK      &mkp MCLK    &none      &none
&none  &none      &none      &none         &none          &none      &none      &none            &none          &none        &none      &none
&none  &none      &none      &mkp MCLK     &mkp RCLK      &mkp LCLK  &mkp LCLK  &mkp RCLK        &mkp MCLK      &none        &none      &none
&none  &kp LC(C)  &kp LC(Z)  &kp LC(V)     &kp LC(Y)      &kp ENTER  &kp RC(T)  &kp RC(RS(TAB))  &kp RC(W)      &kp RC(TAB)  &kp RC(T)  &none
            >;

            sensor-bindings = <&encoder_msc_right_left &encoder_msc_up_down>;
        };

        ex_layer {
            display-name = "EXTRA";

            // -----------------------------------------------------------------------------------------
            // | BOOT |      |      |      |      |      |   |      |      |      |      |      | BOOT |
            // |      |      |      |      |      |      |   | BCLR |  BT0 |  BT1 |  BT2 |  BT3 |  BT4 |
            // |      |      |      |      |      |      |   |      |      |      |      |      |      |
            // |      |      |      |      |      |      |   |      |      |      |      |      |      |
            // |      |      |      |      |      |      |   |      |      |      |      |      |      |
            // |      |      |      |      |      |      |   |      |      |      |      |      |      |
            // |      |      |      |      |      |      |   |      |      |      |      |      |      |

            bindings = <
&bootloader  &none  &none  &none  &none  &none  &none       &none         &none         &none         &none         &none
&none        &none  &none  &none  &none  &none  &bt BT_CLR  &bt BT_SEL 0  &bt BT_SEL 1  &bt BT_SEL 2  &bt BT_SEL 3  &bt BT_SEL 4
&none        &none  &none  &none  &none  &none  &none       &none         &none         &none         &none         &none
&none        &none  &none  &none  &none  &none  &none       &none         &none         &none         &none         &none
&none        &none  &none  &none  &none  &none  &none       &none         &none         &none         &none         &none
&none        &none  &none  &none  &none  &none  &none       &none         &none         &none         &none         &none
&none        &none  &none  &none  &none  &none  &none       &none         &none         &none         &none         &none
            >;

            sensor-bindings = <&encoder_msc_right_left &encoder_msc_up_down>;
        };
    };
};
